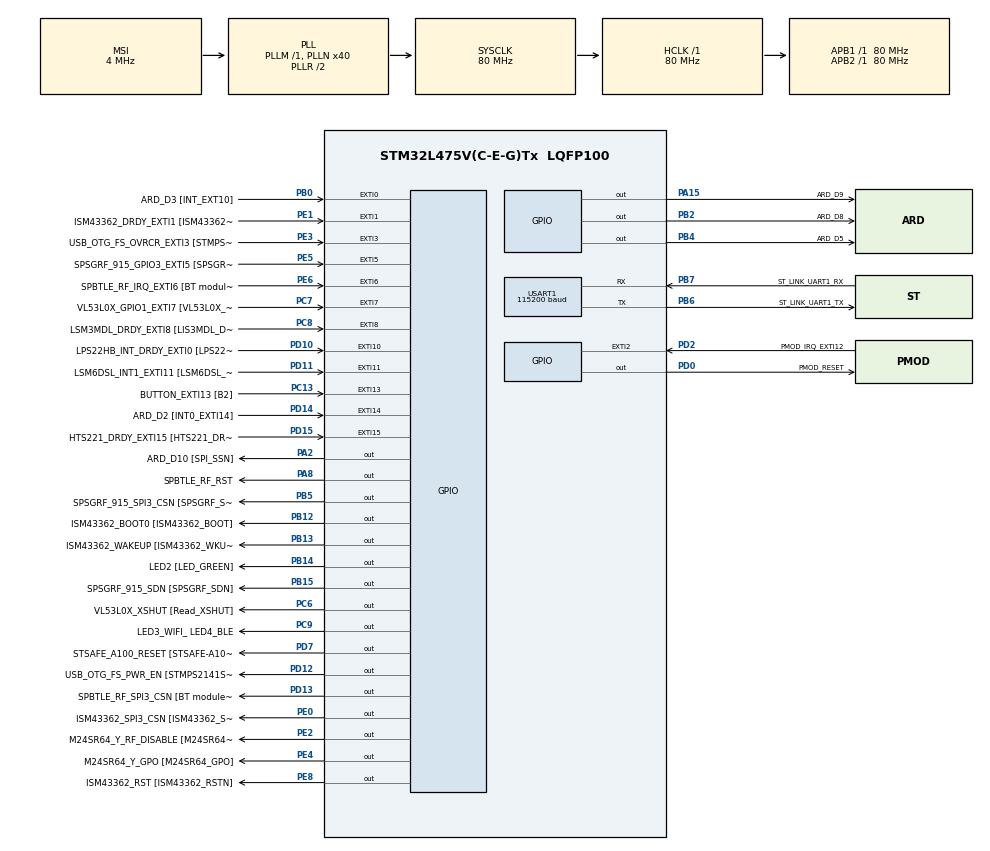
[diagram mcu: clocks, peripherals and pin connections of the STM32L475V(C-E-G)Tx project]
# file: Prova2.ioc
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VP_STMicroelectronics.X-CUBE-AI_VS_ArtificialOoIntelligenceJjXAaCUBEAaAI_6.0.0.Mode=ArtificialOoIntelligenceJjXAaCUBEAaAI
PD12.GPIO_Label=USB_OTG_FS_PWR_EN [STMPS2141STR_EN]
STMicroelectronics.X-CUBE-AI.6.0.0.MaximumSizeOfInputLayer=AI_NETWORK_IN_1_SIZE_BYTES
PC12.Signal=SPI3_MOSI
PB14.GPIO_Label=LED2 [LED_GREEN]
VP_STMicroelectronics.X-CUBE-AI_VS_DeviceJjApplication_6.0.0.Mode=DeviceJjApplication
PC6.GPIO_Label=VL53L0X_XSHUT [Read_XSHUT]
PA6.GPIO_Label=ARD_D12 [SPI1_MISO]
PB6.GPIO_Label=ST_LINK_UART1_TX
PA15\ (JTDI).Signal=GPIO_Output
PC15-OSC32_OUT\ (PC15).Mode=LSE-External-Oscillator
STMicroelectronics.X-CUBE-AI.6.0.0.StackSize=0x1000
PB13.Signal=GPIO_Output
PD6.GPIO_Label=PMOD_UART2_RX
PE6.GPIO_Label=SPBTLE_RF_IRQ_EXTI6 [BT module_SPI_IRQ]
RCC.SYSCLKSource=RCC_SYSCLKSOURCE_PLLCLK
PC14-OSC32_IN\ (PC14).Mode=LSE-External-Oscillator
SH.ADCx_IN16.0=ADC1_IN16
PA14\ (JTCK-SWCLK).Signal=SYS_JTCK-SWCLK
PD4.Signal=USART2_RTS
RCC.APB2TimFreq_Value=80000000
PB6.Signal=USART1_TX
PC7.Signal=GPXTI7
PB6.Mode=Asynchronous
PC3.Signal=ADCx_IN4
STMicroelectronics.X-CUBE-AI.6.0.0.ModelKind-957aa81f0fcb858bb1cf19130b993716af9419c34376cf5e677fe31cccc0c3db=KERAS
PD0.Signal=GPIO_Output
PD8.Signal=USART3_TX
PE5.Signal=GPXTI5
PE1.Signal=GPXTI1
STMicroelectronics.X-CUBE-AI.6.0.0.ModelActualCompression-957aa81f0fcb858bb1cf19130b993716af9419c34376cf5e677fe31cccc0c3db=0.0
PB2.Signal=GPIO_Output
PD1.GPIO_Label=PMOD_SPI2_SCK
PB12.GPIO_Label=ISM43362_BOOT0 [ISM43362_BOOT]
PC4.GPIO_Label=ARD_A1 [ADC]
PE9.Signal=S_CKOUTDFSDM1
PB1.GPIO_Label=ARD_D6 [ADC1_IN6]
NVIC.TIM2_IRQn=true\:0\:0\:false\:false\:true\:true\:true
PE4.GPIO_Label=M24SR64_Y_GPO [M24SR64_GPO]
PE2.Signal=GPIO_Output
PA8.Signal=GPIO_Output
PE10.Signal=QUADSPI_CLK
PA0.Signal=UART4_TX
Mcu.Package=LQFP100
PB9.Signal=I2C1_SDA
TIM2.Prescaler=999
PB1.Signal=ADCx_IN16
PB14.GPIO_PuPd=GPIO_NOPULL
SH.ADCx_IN14.0=ADC1_IN14
PD12.Signal=GPIO_Output
PA10.Signal=USB_OTG_FS_ID
PE12.GPIO_Label=OQUADSPI_BK1_IO0 [MX25R6435F_IO0]
SH.ADCx_IN9.0=ADC1_IN9
RCC.APB1TimFreq_Value=80000000
PA13\ (JTMS-SWDIO).Signal=SYS_JTMS-SWDIO
PE10.GPIO_Label=QUADSPI_CLK [MX25R6435F_SCLK]
PH0-OSC_IN\ (PH0).Mode=HSE-External-Oscillator
PA4.GPIO_Label=ARD_D7
PD15.Signal=GPXTI15
PD9.GPIO_Label=INTERNAL_UART3_RX [ISM43362_TX]
STMicroelectronics.X-CUBE-AI.6.0.0.ModelStructureFile-957aa81f0fcb858bb1cf19130b993716af9419c34376cf5e677fe31cccc0c3db=C\:\\Users\\user\\Desktop\\model_MCG_indoor.h5
PA9.GPIO_Label=USB_OTG_FS_VBUS [STMPS2141STR_OUT]
PC13.Signal=GPXTI13
PD3.Signal=USART2_CTS
STMicroelectronics.X-CUBE-AI.6.0.0.MaximumSizeOfOutputLayer=AI_NETWORK_OUT_1_SIZE_BYTES
PC2.Signal=ADCx_IN3
PC6.Signal=GPIO_Output
PB11.GPIO_Label=INTERNAL_I2C2_SDA [VL53L0X_SDA]
PD7.Signal=GPIO_Output
PD1.Signal=SPI2_SCK
PA11.GPIO_Label=USB_OTG_FS_DM
PC0.Signal=ADCx_IN1
PD10.Signal=GPXTI10
PB8.GPIO_Label=ARD_D15 [I2C1_SCL]
STMicroelectronics.X-CUBE-AI.6.0.0.ModelHashList=957aa81f0fcb858bb1cf19130b993716af9419c34376cf5e677fe31cccc0c3db
PA8.GPIO_Label=SPBTLE_RF_RST
PE8.GPIO_Label=ISM43362_RST [ISM43362_RSTN]
PA9.Signal=USB_OTG_FS_VBUS
STMicroelectronics.X-CUBE-AI.6.0.0.WorkingBufferStartAddrList=0xFFFFFFFF
STMicroelectronics.X-CUBE-AI.6.0.0.ModelNameList=network
PE9.GPIO_Label=DFSDM1_CKOUT [MP34DT01_CLK]
PB10.Signal=I2C2_SCL
PB14.Signal=GPIO_Output
PA5.Signal=SPI1_SCK
PE1.GPIO_Label=ISM43362_DRDY_EXTI1 [ISM43362_DATARDY]
STMicroelectronics.X-CUBE-AI.6.0.0.ModelCompression-957aa81f0fcb858bb1cf19130b993716af9419c34376cf5e677fe31cccc0c3db=1
PE14.Signal=QUADSPI_BK1_IO2
PE15.Signal=QUADSPI_BK1_IO3
PB15.GPIO_Label=SPSGRF_915_SDN [SPSGRF_SDN]
PE8.Signal=GPIO_Output
PA1.GPIO_Label=ARD_D0 [UART4_RX]
SH.ADCx_IN4.0=ADC1_IN4
TIM2.Period=7399
STMicroelectronics.X-CUBE-AI.6.0.0.ModelRamOccupation-957aa81f0fcb858bb1cf19130b993716af9419c34376cf5e677fe31cccc0c3db=39088
PC7.GPIO_Label=VL53L0X_GPIO1_EXTI7 [VL53L0X_GPIO1]
PA4.Signal=ADCx_IN9
PB5.Signal=GPIO_Output
PE13.GPIO_Label=QUADSPI_BK1_IO1 [MX25R6435F_IO1]
PA5.GPIO_Label=ARD_D13 [SPI1_SCK]
PD11.Signal=GPXTI11
PE5.GPIO_Label=SPSGRF_915_GPIO3_EXTI5 [SPSGRF_GPIO_3]
PC12.GPIO_Label=INTERNAL_SPI3_MOSI [BT module_SPI_MOSI] [ISM43362_MOSI]
PA11.Signal=USB_OTG_FS_DM
STMicroelectronics.X-CUBE-AI.6.0.0.MaximumNumberOfInputLayer=1
ProjectManager.HeapSize=0x200
NVIC.PriorityGroup=NVIC_PRIORITYGROUP_4
PE3.Signal=GPXTI3
PC3.GPIO_Label=ARD_A2 [ADC]
PB4\ (NJTRST).GPIO_Label=ARD_D5
PD2.Signal=GPXTI2
PB0.Signal=GPXTI0
PC1.Signal=ADCx_IN2
PD2.GPIO_Label=PMOD_IRQ_EXTI12
Mcu.Family=STM32L4
RCC.CortexFreq_Value=80000000
STMicroelectronics.X-CUBE-AI.6.0.0.ModelFlashOccupation-957aa81f0fcb858bb1cf19130b993716af9419c34376cf5e677fe31cccc0c3db=32464
PH0-OSC_IN\ (PH0).Signal=RCC_OSC_IN
PE11.GPIO_Label=QUADSPI_NCS [MX25R6435F_SCLK]
USART1.BaudRate=115200
SH.ADCx_IN2.0=ADC1_IN2
PC10.Signal=SPI3_SCK
PA0.GPIO_Label=ARD_D1 [UART4_TX]
PC0.GPIO_Label=ARD_A5 [ADC]
PD0.GPIO_Label=PMOD_RESET
PB0.GPIO_Label=ARD_D3 [INT_EXT10]
PC13.GPIO_Label=BUTTON_EXTI13 [B2]
PB13.GPIO_Label=ISM43362_WAKEUP [ISM43362_WKUP]
PB11.Signal=I2C2_SDA
PB15.Signal=GPIO_Output
ProjectManager.StackSize=0x1000
PB3\ (JTDO-TRACESWO).Signal=SYS_JTDO-SWO
PD13.Signal=GPIO_Output
PA12.Signal=USB_OTG_FS_DP
PD11.GPIO_Label=LSM6DSL_INT1_EXTI11 [LSM6DSL_INT1]
RCC.HCLKFreq_Value=80000000
SH.ADCx_IN3.0=ADC1_IN3
TIM3.Period=8399
PB5.PinState=GPIO_PIN_SET
RCC.AHBFreq_Value=80000000
PH1-OSC_OUT\ (PH1).Mode=HSE-External-Oscillator
RCC.HSE_VALUE=8000000
PE13.Signal=QUADSPI_BK1_IO1
STMicroelectronics.X-CUBE-AI.6.0.0.XAaCUBEAaAICcArtificialOoIntelligenceJjCore=true
TIM3.Prescaler=9999
PC11.GPIO_Label=INTERNAL_SPI3_MISO [BT module_SPI_MISO] [ISM43362_MISO]
PA10.GPIO_Label=USB_OTG_FS_ID
PB7.Signal=USART1_RX
PE4.Signal=GPIO_Output
PD7.GPIO_Label=STSAFE_A100_RESET [STSAFE-A100_RESET]
PB7.GPIO_Label=ST_LINK_UART1_RX
PD13.GPIO_Label=SPBTLE_RF_SPI3_CSN [BT module_SPI_CS]
PA6.Signal=SPI1_MISO
PD5.GPIO_Label=PMOD_UART2_TX
PA2.GPIO_Label=ARD_D10 [SPI_SSN]
PE0.GPIO_Label=ISM43362_SPI3_CSN [ISM43362_SSN]
SH.ADCx_IN1.0=ADC1_IN1
PB5.GPIO_Label=SPSGRF_915_SPI3_CSN [SPSGRF_SPI_CS]
PC5.Signal=ADCx_IN14
PD3.GPIO_Label=PMOD_UART2_CTS
PE7.Signal=S_DATAIN2DFSDM1
PD6.Signal=USART2_RX
PE2.GPIO_Label=M24SR64_Y_RF_DISABLE [M24SR64_RFDIS]
PC2.GPIO_Label=ARD_A3 [ADC]
VP_TIM3_VS_ClockSourceINT.Mode=Internal
RCC.PLLSAI1N=24
PA3.Signal=S_TIM2_CH4
RCC.MSI_VALUE=4000000
SH.ADCx_IN13.0=ADC1_IN13
PD15.GPIO_Label=HTS221_DRDY_EXTI15 [HTS221_DRDY]
PB9.GPIO_Label=ARD_D14 [I2C1_SDA]
PC10.GPIO_Label=INTERNAL_SPI3_SCK [BT module_SPI_SCLK] [ISM43362_SCK]
PC9.GPIO_Label=LED3_WIFI_ LED4_BLE
STMicroelectronics.X-CUBE-AI.6.0.0.ModelType-957aa81f0fcb858bb1cf19130b993716af9419c34376cf5e677fe31cccc0c3db=Saved model
PC11.Signal=SPI3_MISO
PC8.Signal=GPXTI8
PC4.Signal=ADCx_IN13
SH.S_DATAIN2DFSDM1.0=DFSDM1_DATIN2
PE14.GPIO_Label=QUAD_SPI_BK1_IO2 [MX25R6435F_IO2]
PC15-OSC32_OUT\ (PC15).Signal=RCC_OSC32_OUT
PD9.Signal=USART3_RX
PD5.Signal=USART2_TX
PA14\ (JTCK-SWCLK).GPIO_Label=SYS_JTCK_SWCLK
PB3\ (JTDO-TRACESWO).GPIO_Label=SYS_JTD0_SWO
STMicroelectronics.X-CUBE-AI.6.0.0.LatestDirectoryUsed-957aa81f0fcb858bb1cf19130b993716af9419c34376cf5e677fe31cccc0c3db=C\:\\Users\\user\\Desktop
PA12.GPIO_Label=USB_OTG_FS_DP
PH1-OSC_OUT\ (PH1).Signal=RCC_OSC_OUT
PD8.GPIO_Label=INTERNAL_UART3_TX [ISM43362_RX]
PC8.GPIO_Label=LSM3MDL_DRDY_EXTI8 [LIS3MDL_DRDY]
USART1.VirtualMode-Asynchronous=VM_ASYNC
PE0.PinState=GPIO_PIN_SET
PB14.PinState=GPIO_PIN_RESET
PE15.GPIO_Label=QUAD_SPI_BK1_IO3 [MX25R6435F_IO3]
ProjectManager.TargetToolchain=STM32CubeIDE
PB10.GPIO_Label=INTERNAL_I2C2_SCL [VL53L0X_SCL]
STMicroelectronics.X-CUBE-AI.6.0.0.InternalRamActivationBufferMaxSize=AI_NETWORK_DATA_ACTIVATIONS_SIZE
RCC.USBFreq_Value=48000000
PD10.GPIO_Label=LPS22HB_INT_DRDY_EXTI0 [LPS22HB_INT_DRDY] 
STMicroelectronics.X-CUBE-AI.6.0.0.MaximumNumberOfOutputLayer=1
PE11.Signal=QUADSPI_NCS
PB14.GPIO_ModeDefaultOutputPP=GPIO_MODE_OUTPUT_PP
PA1.Signal=UART4_RX
STMicroelectronics.X-CUBE-AI.6.0.0.ModelName-957aa81f0fcb858bb1cf19130b993716af9419c34376cf5e677fe31cccc0c3db=network
board=B-L475E-IOT01A2
RCC.VCOOutputFreq_Value=160000000
RCC.APB2Freq_Value=80000000
PA13\ (JTMS-SWDIO).GPIO_Label=SYS_JTMS_SWDIO
VP_TIM2_VS_ClockSourceINT.Mode=Internal
PD4.GPIO_Label=PMOD_UART2_RTS
SH.S_CKOUTDFSDM1.0=DFSDM1_CKOUT
RCC.ADCFreq_Value=48000000
PC1.GPIO_Label=ARD_A4 [ADC]
PD14.GPIO_Label=ARD_D2 [INT0_EXTI14]
PE6.Signal=GPXTI6
STMicroelectronics.X-CUBE-AI.6.0.0.ApplicationCcDeviceJjApplication=ApplicationTemplate
PA15\ (JTDI).GPIO_Label=ARD_D9
Mcu.Name=STM32L475V(C-E-G)Tx
PE0.Signal=GPIO_Output
PE7.GPIO_Label=DFSDM1_DATIN2 [MP34DT01_DOUT]
PE12.Signal=QUADSPI_BK1_IO0
PA2.Signal=GPIO_Output
PD14.Signal=GPXTI14
RCC.SYSCLKFreq_VALUE=80000000
PA7.GPIO_Label=ARD_D11 [SPI1_MOSI]
PC13.GPIO_ModeDefaultEXTI=GPIO_MODE_IT_FALLING
PC5.GPIO_Label=ARD_A0 [ADC]
PC14-OSC32_IN\ (PC14).Signal=RCC_OSC32_IN
STMicroelectronics.X-CUBE-AI.6.0.0.ModelMacc-957aa81f0fcb858bb1cf19130b993716af9419c34376cf5e677fe31cccc0c3db=956496
PB7.Mode=Asynchronous
PB2.GPIO_Label=ARD_D8
SH.S_TIM2_CH4.0=TIM2_CH4
STMicroelectronics.X-CUBE-AI.6.0.0.HeapSize=0x200
RCC.HSI_VALUE=16000000
RCC.PLLN=40
PB8.Signal=I2C1_SCL
PE3.GPIO_Label=USB_OTG_FS_OVRCR_EXTI3 [STMPS2141STR_FAULT]
PC9.Signal=GPIO_Output
PD13.PinState=GPIO_PIN_SET
RCC.APB1Freq_Value=80000000
VP_CRC_VS_CRC.Mode=CRC_Activate
STMicroelectronics.X-CUBE-AI.6.0.0.ActivationBufferSizeList=39088
PB12.Signal=GPIO_Output
PA3.GPIO_Label=ARD_D4
PA7.Signal=SPI1_MOSI
PB4\ (NJTRST).Signal=GPIO_Output

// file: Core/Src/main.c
/* USER CODE BEGIN Header */
/**
  ******************************************************************************
  * @file           : main.c
  * @brief          : Main program body
  ******************************************************************************
  * @attention
  *
  * <h2><center>&copy; Copyright (c) 2021 STMicroelectronics.
  * All rights reserved.</center></h2>
  *
  * This software component is licensed by ST under BSD 3-Clause license,
  * the "License"; You may not use this file except in compliance with the
  * License. You may obtain a copy of the License at:
  *                        opensource.org/licenses/BSD-3-Clause
  *
  ******************************************************************************
  */
/* USER CODE END Header */
#include "main.h"
#include "app_x-cube-ai.h"

/* USER CODE BEGIN Includes */
//vengono importate le librerie necessarie
#include "stm32l475e_iot01.h"
#include "stm32l475e_iot01_accelero.h"
#include "stm32l475e_iot01_gyro.h"
#include <math.h>
/* USER CODE END Includes */

CRC_HandleTypeDef hcrc;

TIM_HandleTypeDef htim2;
TIM_HandleTypeDef htim3;

UART_HandleTypeDef huart1;

void SystemClock_Config(void);
static void MX_GPIO_Init(void);
static void MX_CRC_Init(void);
static void MX_TIM2_Init(void);
static void MX_USART1_UART_Init(void);
static void MX_TIM3_Init(void);

int main(void)
{

  /* MCU Configuration--------------------------------------------------------*/

  /* Reset of all peripherals, Initializes the Flash interface and the Systick. */
  HAL_Init();

  /* Configure the system clock */
  SystemClock_Config();

  /* Initialize all configured peripherals */
  MX_GPIO_Init();
  MX_CRC_Init();
  MX_TIM2_Init();
  MX_USART1_UART_Init();
  MX_TIM3_Init();
  MX_X_CUBE_AI_Init();
  /* USER CODE BEGIN 2 */
  //vengono inizializzati i sensori e avviati i timer
  BSP_GYRO_Init();
  BSP_ACCELERO_Init();
  HAL_TIM_Base_Start_IT(&htim2);
  HAL_TIM_Base_Start_IT(&htim3);
  /* USER CODE END 2 */

  /* Infinite loop */
  while (1)
  {

//  MX_X_CUBE_AI_Process();
  }
}

void SystemClock_Config(void)
{
  RCC_OscInitTypeDef RCC_OscInitStruct = {0};
  RCC_ClkInitTypeDef RCC_ClkInitStruct = {0};
  RCC_PeriphCLKInitTypeDef PeriphClkInit = {0};

  /** Configure LSE Drive Capability
  */
  HAL_PWR_EnableBkUpAccess();
  __HAL_RCC_LSEDRIVE_CONFIG(RCC_LSEDRIVE_LOW);
  /** Initializes the RCC Oscillators according to the specified parameters
  * in the RCC_OscInitTypeDef structure.
  */
  RCC_OscInitStruct.OscillatorType = RCC_OSCILLATORTYPE_LSE|RCC_OSCILLATORTYPE_MSI;
  RCC_OscInitStruct.LSEState = RCC_LSE_ON;
  RCC_OscInitStruct.MSIState = RCC_MSI_ON;
  RCC_OscInitStruct.MSICalibrationValue = 0;
  RCC_OscInitStruct.MSIClockRange = RCC_MSIRANGE_6;
  RCC_OscInitStruct.PLL.PLLState = RCC_PLL_ON;
  RCC_OscInitStruct.PLL.PLLSource = RCC_PLLSOURCE_MSI;
  RCC_OscInitStruct.PLL.PLLM = 1;
  RCC_OscInitStruct.PLL.PLLN = 40;
  RCC_OscInitStruct.PLL.PLLP = RCC_PLLP_DIV7;
  RCC_OscInitStruct.PLL.PLLQ = RCC_PLLQ_DIV2;
  RCC_OscInitStruct.PLL.PLLR = RCC_PLLR_DIV2;
  if (HAL_RCC_OscConfig(&RCC_OscInitStruct) != HAL_OK)
  {
    Error_Handler();
  }
  /** Initializes the CPU, AHB and APB buses clocks
  */
  RCC_ClkInitStruct.ClockType = RCC_CLOCKTYPE_HCLK|RCC_CLOCKTYPE_SYSCLK
                              |RCC_CLOCKTYPE_PCLK1|RCC_CLOCKTYPE_PCLK2;
  RCC_ClkInitStruct.SYSCLKSource = RCC_SYSCLKSOURCE_PLLCLK;
  RCC_ClkInitStruct.AHBCLKDivider = RCC_SYSCLK_DIV1;
  RCC_ClkInitStruct.APB1CLKDivider = RCC_HCLK_DIV1;
  RCC_ClkInitStruct.APB2CLKDivider = RCC_HCLK_DIV1;

  if (HAL_RCC_ClockConfig(&RCC_ClkInitStruct, FLASH_LATENCY_4) != HAL_OK)
  {
    Error_Handler();
  }
  PeriphClkInit.PeriphClockSelection = RCC_PERIPHCLK_USART1;
  PeriphClkInit.Usart1ClockSelection = RCC_USART1CLKSOURCE_PCLK2;
  if (HAL_RCCEx_PeriphCLKConfig(&PeriphClkInit) != HAL_OK)
  {
    Error_Handler();
  }
  /** Configure the main internal regulator output voltage
  */
  if (HAL_PWREx_ControlVoltageScaling(PWR_REGULATOR_VOLTAGE_SCALE1) != HAL_OK)
  {
    Error_Handler();
  }
  /** Enable MSI Auto calibration
  */
  HAL_RCCEx_EnableMSIPLLMode();
}

static void MX_CRC_Init(void)
{

  hcrc.Instance = CRC;
  hcrc.Init.DefaultPolynomialUse = DEFAULT_POLYNOMIAL_ENABLE;
  hcrc.Init.DefaultInitValueUse = DEFAULT_INIT_VALUE_ENABLE;
  hcrc.Init.InputDataInversionMode = CRC_INPUTDATA_INVERSION_NONE;
  hcrc.Init.OutputDataInversionMode = CRC_OUTPUTDATA_INVERSION_DISABLE;
  hcrc.InputDataFormat = CRC_INPUTDATA_FORMAT_BYTES;
  if (HAL_CRC_Init(&hcrc) != HAL_OK)
  {
    Error_Handler();
  }

}

static void MX_TIM2_Init(void)
{

  TIM_ClockConfigTypeDef sClockSourceConfig = {0};
  TIM_MasterConfigTypeDef sMasterConfig = {0};

  htim2.Instance = TIM2;
  htim2.Init.Prescaler = 999;
  htim2.Init.CounterMode = TIM_COUNTERMODE_UP;
  htim2.Init.Period = 7399;
  htim2.Init.ClockDivision = TIM_CLOCKDIVISION_DIV1;
  htim2.Init.AutoReloadPreload = TIM_AUTORELOAD_PRELOAD_DISABLE;
  if (HAL_TIM_Base_Init(&htim2) != HAL_OK)
  {
    Error_Handler();
  }
  sClockSourceConfig.ClockSource = TIM_CLOCKSOURCE_INTERNAL;
  if (HAL_TIM_ConfigClockSource(&htim2, &sClockSourceConfig) != HAL_OK)
  {
    Error_Handler();
  }
  sMasterConfig.MasterOutputTrigger = TIM_TRGO_RESET;
  sMasterConfig.MasterSlaveMode = TIM_MASTERSLAVEMODE_DISABLE;
  if (HAL_TIMEx_MasterConfigSynchronization(&htim2, &sMasterConfig) != HAL_OK)
  {
    Error_Handler();
  }

}

static void MX_TIM3_Init(void)
{

  TIM_ClockConfigTypeDef sClockSourceConfig = {0};
  TIM_MasterConfigTypeDef sMasterConfig = {0};

  htim3.Instance = TIM3;
  htim3.Init.Prescaler = 9999;
  htim3.Init.CounterMode = TIM_COUNTERMODE_UP;
  htim3.Init.Period = 8399;
  htim3.Init.ClockDivision = TIM_CLOCKDIVISION_DIV1;
  htim3.Init.AutoReloadPreload = TIM_AUTORELOAD_PRELOAD_DISABLE;
  if (HAL_TIM_Base_Init(&htim3) != HAL_OK)
  {
    Error_Handler();
  }
  sClockSourceConfig.ClockSource = TIM_CLOCKSOURCE_INTERNAL;
  if (HAL_TIM_ConfigClockSource(&htim3, &sClockSourceConfig) != HAL_OK)
  {
    Error_Handler();
  }
  sMasterConfig.MasterOutputTrigger = TIM_TRGO_RESET;
  sMasterConfig.MasterSlaveMode = TIM_MASTERSLAVEMODE_DISABLE;
  if (HAL_TIMEx_MasterConfigSynchronization(&htim3, &sMasterConfig) != HAL_OK)
  {
    Error_Handler();
  }

}

static void MX_USART1_UART_Init(void)
{

  huart1.Instance = USART1;
  huart1.Init.BaudRate = 115200;
  huart1.Init.WordLength = UART_WORDLENGTH_8B;
  huart1.Init.StopBits = UART_STOPBITS_1;
  huart1.Init.Parity = UART_PARITY_NONE;
  huart1.Init.Mode = UART_MODE_TX_RX;
  huart1.Init.HwFlowCtl = UART_HWCONTROL_NONE;
  huart1.Init.OverSampling = UART_OVERSAMPLING_16;
  huart1.Init.OneBitSampling = UART_ONE_BIT_SAMPLE_DISABLE;
  huart1.AdvancedInit.AdvFeatureInit = UART_ADVFEATURE_NO_INIT;
  if (HAL_UART_Init(&huart1) != HAL_OK)
  {
    Error_Handler();
  }

}

static void MX_GPIO_Init(void)
{
  GPIO_InitTypeDef GPIO_InitStruct = {0};

  /* GPIO Ports Clock Enable */
  __HAL_RCC_GPIOE_CLK_ENABLE();
  __HAL_RCC_GPIOC_CLK_ENABLE();
  __HAL_RCC_GPIOH_CLK_ENABLE();
  __HAL_RCC_GPIOA_CLK_ENABLE();
  __HAL_RCC_GPIOB_CLK_ENABLE();
  __HAL_RCC_GPIOD_CLK_ENABLE();

  /*Configure GPIO pin Output Level */
  HAL_GPIO_WritePin(GPIOE, M24SR64_Y_RF_DISABLE_Pin|M24SR64_Y_GPO_Pin|ISM43362_RST_Pin, GPIO_PIN_RESET);

  /*Configure GPIO pin Output Level */
  HAL_GPIO_WritePin(GPIOA, ARD_D10_Pin|SPBTLE_RF_RST_Pin|ARD_D9_Pin, GPIO_PIN_RESET);

  /*Configure GPIO pin Output Level */
  HAL_GPIO_WritePin(GPIOB, ARD_D8_Pin|ISM43362_BOOT0_Pin|ISM43362_WAKEUP_Pin|LED2_Pin
                          |SPSGRF_915_SDN_Pin|ARD_D5_Pin, GPIO_PIN_RESET);

  /*Configure GPIO pin Output Level */
  HAL_GPIO_WritePin(GPIOD, USB_OTG_FS_PWR_EN_Pin|PMOD_RESET_Pin|STSAFE_A100_RESET_Pin, GPIO_PIN_RESET);

  /*Configure GPIO pin Output Level */
  HAL_GPIO_WritePin(SPBTLE_RF_SPI3_CSN_GPIO_Port, SPBTLE_RF_SPI3_CSN_Pin, GPIO_PIN_SET);

  /*Configure GPIO pin Output Level */
  HAL_GPIO_WritePin(GPIOC, VL53L0X_XSHUT_Pin|LED3_WIFI__LED4_BLE_Pin, GPIO_PIN_RESET);

  /*Configure GPIO pin Output Level */
  HAL_GPIO_WritePin(SPSGRF_915_SPI3_CSN_GPIO_Port, SPSGRF_915_SPI3_CSN_Pin, GPIO_PIN_SET);

  /*Configure GPIO pin Output Level */
  HAL_GPIO_WritePin(ISM43362_SPI3_CSN_GPIO_Port, ISM43362_SPI3_CSN_Pin, GPIO_PIN_SET);

  /*Configure GPIO pins : M24SR64_Y_RF_DISABLE_Pin M24SR64_Y_GPO_Pin ISM43362_RST_Pin ISM43362_SPI3_CSN_Pin */
  GPIO_InitStruct.Pin = M24SR64_Y_RF_DISABLE_Pin|M24SR64_Y_GPO_Pin|ISM43362_RST_Pin|ISM43362_SPI3_CSN_Pin;
  GPIO_InitStruct.Mode = GPIO_MODE_OUTPUT_PP;
  GPIO_InitStruct.Pull = GPIO_NOPULL;
  GPIO_InitStruct.Speed = GPIO_SPEED_FREQ_LOW;
  HAL_GPIO_Init(GPIOE, &GPIO_InitStruct);

  /*Configure GPIO pins : USB_OTG_FS_OVRCR_EXTI3_Pin SPSGRF_915_GPIO3_EXTI5_Pin SPBTLE_RF_IRQ_EXTI6_Pin ISM43362_DRDY_EXTI1_Pin */
  GPIO_InitStruct.Pin = USB_OTG_FS_OVRCR_EXTI3_Pin|SPSGRF_915_GPIO3_EXTI5_Pin|SPBTLE_RF_IRQ_EXTI6_Pin|ISM43362_DRDY_EXTI1_Pin;
  GPIO_InitStruct.Mode = GPIO_MODE_IT_RISING;
  GPIO_InitStruct.Pull = GPIO_NOPULL;
  HAL_GPIO_Init(GPIOE, &GPIO_InitStruct);

  /*Configure GPIO pin : BUTTON_EXTI13_Pin */
  GPIO_InitStruct.Pin = BUTTON_EXTI13_Pin;
  GPIO_InitStruct.Mode = GPIO_MODE_IT_FALLING;
  GPIO_InitStruct.Pull = GPIO_NOPULL;
  HAL_GPIO_Init(BUTTON_EXTI13_GPIO_Port, &GPIO_InitStruct);

  /*Configure GPIO pins : ARD_A5_Pin ARD_A4_Pin ARD_A3_Pin ARD_A2_Pin
                           ARD_A1_Pin ARD_A0_Pin */
  GPIO_InitStruct.Pin = ARD_A5_Pin|ARD_A4_Pin|ARD_A3_Pin|ARD_A2_Pin
                          |ARD_A1_Pin|ARD_A0_Pin;
  GPIO_InitStruct.Mode = GPIO_MODE_ANALOG_ADC_CONTROL;
  GPIO_InitStruct.Pull = GPIO_NOPULL;
  HAL_GPIO_Init(GPIOC, &GPIO_InitStruct);

  /*Configure GPIO pins : ARD_D1_Pin ARD_D0_Pin */
  GPIO_InitStruct.Pin = ARD_D1_Pin|ARD_D0_Pin;
  GPIO_InitStruct.Mode = GPIO_MODE_AF_PP;
  GPIO_InitStruct.Pull = GPIO_NOPULL;
  GPIO_InitStruct.Speed = GPIO_SPEED_FREQ_VERY_HIGH;
  GPIO_InitStruct.Alternate = GPIO_AF8_UART4;
  HAL_GPIO_Init(GPIOA, &GPIO_InitStruct);

  /*Configure GPIO pins : ARD_D10_Pin SPBTLE_RF_RST_Pin ARD_D9_Pin */
  GPIO_InitStruct.Pin = ARD_D10_Pin|SPBTLE_RF_RST_Pin|ARD_D9_Pin;
  GPIO_InitStruct.Mode = GPIO_MODE_OUTPUT_PP;
  GPIO_InitStruct.Pull = GPIO_NOPULL;
  GPIO_InitStruct.Speed = GPIO_SPEED_FREQ_LOW;
  HAL_GPIO_Init(GPIOA, &GPIO_InitStruct);

  /*Configure GPIO pin : ARD_D7_Pin */
  GPIO_InitStruct.Pin = ARD_D7_Pin;
  GPIO_InitStruct.Mode = GPIO_MODE_ANALOG_ADC_CONTROL;
  GPIO_InitStruct.Pull = GPIO_NOPULL;
  HAL_GPIO_Init(ARD_D7_GPIO_Port, &GPIO_InitStruct);

  /*Configure GPIO pins : ARD_D13_Pin ARD_D12_Pin ARD_D11_Pin */
  GPIO_InitStruct.Pin = ARD_D13_Pin|ARD_D12_Pin|ARD_D11_Pin;
  GPIO_InitStruct.Mode = GPIO_MODE_AF_PP;
  GPIO_InitStruct.Pull = GPIO_NOPULL;
  GPIO_InitStruct.Speed = GPIO_SPEED_FREQ_VERY_HIGH;
  GPIO_InitStruct.Alternate = GPIO_AF5_SPI1;
  HAL_GPIO_Init(GPIOA, &GPIO_InitStruct);

  /*Configure GPIO pin : ARD_D3_Pin */
  GPIO_InitStruct.Pin = ARD_D3_Pin;
  GPIO_InitStruct.Mode = GPIO_MODE_IT_RISING;
  GPIO_InitStruct.Pull = GPIO_NOPULL;
  HAL_GPIO_Init(ARD_D3_GPIO_Port, &GPIO_InitStruct);

  /*Configure GPIO pin : ARD_D6_Pin */
  GPIO_InitStruct.Pin = ARD_D6_Pin;
  GPIO_InitStruct.Mode = GPIO_MODE_ANALOG_ADC_CONTROL;
  GPIO_InitStruct.Pull = GPIO_NOPULL;
  HAL_GPIO_Init(ARD_D6_GPIO_Port, &GPIO_InitStruct);

  /*Configure GPIO pins : ARD_D8_Pin ISM43362_BOOT0_Pin ISM43362_WAKEUP_Pin LED2_Pin
                           SPSGRF_915_SDN_Pin ARD_D5_Pin SPSGRF_915_SPI3_CSN_Pin */
  GPIO_InitStruct.Pin = ARD_D8_Pin|ISM43362_BOOT0_Pin|ISM43362_WAKEUP_Pin|LED2_Pin
                          |SPSGRF_915_SDN_Pin|ARD_D5_Pin|SPSGRF_915_SPI3_CSN_Pin;
  GPIO_InitStruct.Mode = GPIO_MODE_OUTPUT_PP;
  GPIO_InitStruct.Pull = GPIO_NOPULL;
  GPIO_InitStruct.Speed = GPIO_SPEED_FREQ_LOW;
  HAL_GPIO_Init(GPIOB, &GPIO_InitStruct);

  /*Configure GPIO pins : DFSDM1_DATIN2_Pin DFSDM1_CKOUT_Pin */
  GPIO_InitStruct.Pin = DFSDM1_DATIN2_Pin|DFSDM1_CKOUT_Pin;
  GPIO_InitStruct.Mode = GPIO_MODE_AF_PP;
  GPIO_InitStruct.Pull = GPIO_NOPULL;
  GPIO_InitStruct.Speed = GPIO_SPEED_FREQ_LOW;
  GPIO_InitStruct.Alternate = GPIO_AF6_DFSDM1;
  HAL_GPIO_Init(GPIOE, &GPIO_InitStruct);

  /*Configure GPIO pins : QUADSPI_CLK_Pin QUADSPI_NCS_Pin OQUADSPI_BK1_IO0_Pin QUADSPI_BK1_IO1_Pin
                           QUAD_SPI_BK1_IO2_Pin QUAD_SPI_BK1_IO3_Pin */
  GPIO_InitStruct.Pin = QUADSPI_CLK_Pin|QUADSPI_NCS_Pin|OQUADSPI_BK1_IO0_Pin|QUADSPI_BK1_IO1_Pin
                          |QUAD_SPI_BK1_IO2_Pin|QUAD_SPI_BK1_IO3_Pin;
  GPIO_InitStruct.Mode = GPIO_MODE_AF_PP;
  GPIO_InitStruct.Pull = GPIO_NOPULL;
  GPIO_InitStruct.Speed = GPIO_SPEED_FREQ_VERY_HIGH;
  GPIO_InitStruct.Alternate = GPIO_AF10_QUADSPI;
  HAL_GPIO_Init(GPIOE, &GPIO_InitStruct);

  /*Configure GPIO pins : INTERNAL_I2C2_SCL_Pin INTERNAL_I2C2_SDA_Pin */
  GPIO_InitStruct.Pin = INTERNAL_I2C2_SCL_Pin|INTERNAL_I2C2_SDA_Pin;
  GPIO_InitStruct.Mode = GPIO_MODE_AF_OD;
  GPIO_InitStruct.Pull = GPIO_PULLUP;
  GPIO_InitStruct.Speed = GPIO_SPEED_FREQ_VERY_HIGH;
  GPIO_InitStruct.Alternate = GPIO_AF4_I2C2;
  HAL_GPIO_Init(GPIOB, &GPIO_InitStruct);

  /*Configure GPIO pins : INTERNAL_UART3_TX_Pin INTERNAL_UART3_RX_Pin */
  GPIO_InitStruct.Pin = INTERNAL_UART3_TX_Pin|INTERNAL_UART3_RX_Pin;
  GPIO_InitStruct.Mode = GPIO_MODE_AF_PP;
  GPIO_InitStruct.Pull = GPIO_NOPULL;
  GPIO_InitStruct.Speed = GPIO_SPEED_FREQ_VERY_HIGH;
  GPIO_InitStruct.Alternate = GPIO_AF7_USART3;
  HAL_GPIO_Init(GPIOD, &GPIO_InitStruct);

  /*Configure GPIO pins : LPS22HB_INT_DRDY_EXTI0_Pin LSM6DSL_INT1_EXTI11_Pin ARD_D2_Pin HTS221_DRDY_EXTI15_Pin
                           PMOD_IRQ_EXTI12_Pin */
  GPIO_InitStruct.Pin = LPS22HB_INT_DRDY_EXTI0_Pin|LSM6DSL_INT1_EXTI11_Pin|ARD_D2_Pin|HTS221_DRDY_EXTI15_Pin
                          |PMOD_IRQ_EXTI12_Pin;
  GPIO_InitStruct.Mode = GPIO_MODE_IT_RISING;
  GPIO_InitStruct.Pull = GPIO_NOPULL;
  HAL_GPIO_Init(GPIOD, &GPIO_InitStruct);

  /*Configure GPIO pins : USB_OTG_FS_PWR_EN_Pin SPBTLE_RF_SPI3_CSN_Pin PMOD_RESET_Pin STSAFE_A100_RESET_Pin */
  GPIO_InitStruct.Pin = USB_OTG_FS_PWR_EN_Pin|SPBTLE_RF_SPI3_CSN_Pin|PMOD_RESET_Pin|STSAFE_A100_RESET_Pin;
  GPIO_InitStruct.Mode = GPIO_MODE_OUTPUT_PP;
  GPIO_InitStruct.Pull = GPIO_NOPULL;
  GPIO_InitStruct.Speed = GPIO_SPEED_FREQ_LOW;
  HAL_GPIO_Init(GPIOD, &GPIO_InitStruct);

  /*Configure GPIO pins : VL53L0X_XSHUT_Pin LED3_WIFI__LED4_BLE_Pin */
  GPIO_InitStruct.Pin = VL53L0X_XSHUT_Pin|LED3_WIFI__LED4_BLE_Pin;
  GPIO_InitStruct.Mode = GPIO_MODE_OUTPUT_PP;
  GPIO_InitStruct.Pull = GPIO_NOPULL;
  GPIO_InitStruct.Speed = GPIO_SPEED_FREQ_LOW;
  HAL_GPIO_Init(GPIOC, &GPIO_InitStruct);

  /*Configure GPIO pins : VL53L0X_GPIO1_EXTI7_Pin LSM3MDL_DRDY_EXTI8_Pin */
  GPIO_InitStruct.Pin = VL53L0X_GPIO1_EXTI7_Pin|LSM3MDL_DRDY_EXTI8_Pin;
  GPIO_InitStruct.Mode = GPIO_MODE_IT_RISING;
  GPIO_InitStruct.Pull = GPIO_NOPULL;
  HAL_GPIO_Init(GPIOC, &GPIO_InitStruct);

  /*Configure GPIO pin : USB_OTG_FS_VBUS_Pin */
  GPIO_InitStruct.Pin = USB_OTG_FS_VBUS_Pin;
  GPIO_InitStruct.Mode = GPIO_MODE_INPUT;
  GPIO_InitStruct.Pull = GPIO_NOPULL;
  HAL_GPIO_Init(USB_OTG_FS_VBUS_GPIO_Port, &GPIO_InitStruct);

  /*Configure GPIO pins : USB_OTG_FS_ID_Pin USB_OTG_FS_DM_Pin USB_OTG_FS_DP_Pin */
  GPIO_InitStruct.Pin = USB_OTG_FS_ID_Pin|USB_OTG_FS_DM_Pin|USB_OTG_FS_DP_Pin;
  GPIO_InitStruct.Mode = GPIO_MODE_AF_PP;
  GPIO_InitStruct.Pull = GPIO_NOPULL;
  GPIO_InitStruct.Speed = GPIO_SPEED_FREQ_VERY_HIGH;
  GPIO_InitStruct.Alternate = GPIO_AF10_OTG_FS;
  HAL_GPIO_Init(GPIOA, &GPIO_InitStruct);

  /*Configure GPIO pins : INTERNAL_SPI3_SCK_Pin INTERNAL_SPI3_MISO_Pin INTERNAL_SPI3_MOSI_Pin */
  GPIO_InitStruct.Pin = INTERNAL_SPI3_SCK_Pin|INTERNAL_SPI3_MISO_Pin|INTERNAL_SPI3_MOSI_Pin;
  GPIO_InitStruct.Mode = GPIO_MODE_AF_PP;
  GPIO_InitStruct.Pull = GPIO_NOPULL;
  GPIO_InitStruct.Speed = GPIO_SPEED_FREQ_VERY_HIGH;
  GPIO_InitStruct.Alternate = GPIO_AF6_SPI3;
  HAL_GPIO_Init(GPIOC, &GPIO_InitStruct);

  /*Configure GPIO pin : PMOD_SPI2_SCK_Pin */
  GPIO_InitStruct.Pin = PMOD_SPI2_SCK_Pin;
  GPIO_InitStruct.Mode = GPIO_MODE_AF_PP;
  GPIO_InitStruct.Pull = GPIO_NOPULL;
  GPIO_InitStruct.Speed = GPIO_SPEED_FREQ_VERY_HIGH;
  GPIO_InitStruct.Alternate = GPIO_AF5_SPI2;
  HAL_GPIO_Init(PMOD_SPI2_SCK_GPIO_Port, &GPIO_InitStruct);

  /*Configure GPIO pins : PMOD_UART2_CTS_Pin PMOD_UART2_RTS_Pin PMOD_UART2_TX_Pin PMOD_UART2_RX_Pin */
  GPIO_InitStruct.Pin = PMOD_UART2_CTS_Pin|PMOD_UART2_RTS_Pin|PMOD_UART2_TX_Pin|PMOD_UART2_RX_Pin;
  GPIO_InitStruct.Mode = GPIO_MODE_AF_PP;
  GPIO_InitStruct.Pull = GPIO_NOPULL;
  GPIO_InitStruct.Speed = GPIO_SPEED_FREQ_VERY_HIGH;
  GPIO_InitStruct.Alternate = GPIO_AF7_USART2;
  HAL_GPIO_Init(GPIOD, &GPIO_InitStruct);

  /*Configure GPIO pins : ARD_D15_Pin ARD_D14_Pin */
  GPIO_InitStruct.Pin = ARD_D15_Pin|ARD_D14_Pin;
  GPIO_InitStruct.Mode = GPIO_MODE_AF_OD;
  GPIO_InitStruct.Pull = GPIO_PULLUP;
  GPIO_InitStruct.Speed = GPIO_SPEED_FREQ_VERY_HIGH;
  GPIO_InitStruct.Alternate = GPIO_AF4_I2C1;
  HAL_GPIO_Init(GPIOB, &GPIO_InitStruct);

}

void Error_Handler(void)
{
  __disable_irq();
  while (1)
  {
  }
}

/************************ (C) COPYRIGHT STMicroelectronics *****END OF FILE****/
